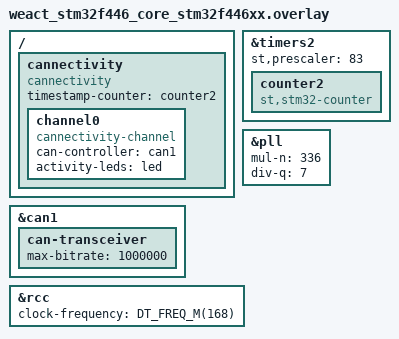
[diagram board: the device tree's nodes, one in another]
/*
 * Copyright (c) 2026 Chris Chatelain <chris@digiex.ca>
 *
 * SPDX-License-Identifier: Apache-2.0
 */

#include <zephyr/dt-bindings/gpio/gpio.h>
#include "../app.overlay"

/ {
	cannectivity: cannectivity {
		compatible = "cannectivity";
		timestamp-counter = <&counter2>;

		channel0 {
			compatible = "cannectivity-channel";
			can-controller = <&can1>;
			activity-leds = <&led>;
		};
	};
};

&can1 {
	can-transceiver {
		max-bitrate = <1000000>;
	};
};

&timers2 {
	status = "okay";
	st,prescaler = <83>;

	counter2: counter2 {
		compatible = "st,stm32-counter";
		status = "okay";
	};
};

/*
 * Override the board's main PLL so PLL_Q lands on exactly 48 MHz, which the
 * USB OTG FS peripheral requires. The board default (N=360, Q=2) yields
 * PLL_Q=180 MHz and the USB device never enumerates.
 *
 * HSE 8 MHz / M=8 = 1 MHz VCO input, * N=336 = 336 MHz VCO,
 *   / P=2 -> 168 MHz SYSCLK
 *   / Q=7 ->  48 MHz USB clock (CK48M_SEL=0 selects PLL_Q, the dtsi default)
 *
 * Note: the F446 CK48M mux can also source PLLSAI, but Zephyr's
 * clock_stm32f2_f4_f7.c references LL_RCC_PLLSAI_GetMainSource() which is not
 * defined in the STM32F4 HAL, so enabling the clk48 node fails to build.
 */
&pll {
	mul-n = <336>;
	div-q = <7>;
};

&rcc {
	clock-frequency = <DT_FREQ_M(168)>;
};
